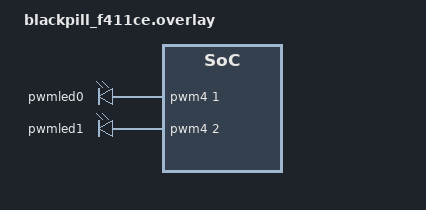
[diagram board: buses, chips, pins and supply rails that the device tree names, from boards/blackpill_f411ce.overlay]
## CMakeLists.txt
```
# SPDX-License-Identifier: BSL-1.0

cmake_minimum_required(VERSION 3.30)

find_package(Zephyr HINTS $ENV{ZEPHYR_BASE})

project(001-cmakepresets-json
        VERSION 1.0.0
        LANGUAGES C ASM
        DESCRIPTION "VS Code CMakePresets.json for Zephyr"
        HOMEPAGE_URL "https://github.com/juanjin-dev/learning-zephyr")

add_subdirectory(src)
```

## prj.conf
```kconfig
# SPDX-License-Identifier: BSL-1.0

CONFIG_PWM=y
CONFIG_LED=y
```

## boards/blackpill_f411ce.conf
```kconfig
# SPDX-License-Identifier: BSL-1.0
```

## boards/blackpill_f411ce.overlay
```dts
/**
 * SPDX-License-Identifier: BSL-1.0
 */

/ {
	pwmleds: pwmleds {
    	status = "okay";
		compatible = "pwm-leds";

		pwmled0: pwmled0 {
			pwms = <&pwm4 1 65535 PWM_POLARITY_NORMAL>;
		};

		pwmled1: pwmled1 {
			pwms = <&pwm4 2 65535 PWM_POLARITY_NORMAL>;
		};
	};
};
```

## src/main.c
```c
/**
 * SPDX-License-Identifier: BSL-1.0
 */

#include <zephyr/kernel.h>
#include <zephyr/drivers/led.h>
struct pwmled_data {
    const struct led_dt_spec pwmled;
    bool dir;
    uint8_t brightness;
};

int main(void) {
    int ret;
    struct k_timer timer;
    struct pwmled_data pwmleds[] = {
        {
            .pwmled = LED_DT_SPEC_GET(DT_NODELABEL(pwmled0)),
            .dir = false,
            .brightness = 0,
        },
        {
            .pwmled = LED_DT_SPEC_GET(DT_NODELABEL(pwmled1)),
            .dir = true,
            .brightness = 100,
        }
    };

    ARRAY_FOR_EACH_PTR(pwmleds, pwmled) {
        if (!led_is_ready_dt(&pwmled->pwmled)) {
            printk("Error: LED %s is not ready\n",
                    pwmled->pwmled.dev->name);
            goto out;
        }
    }

    k_timer_init(&timer, NULL, NULL);
    k_timer_start(&timer, K_NO_WAIT, K_MSEC(5));

    while (true) {
        int elapsed = k_timer_status_sync(&timer);
        if (elapsed > 1) {
            printk("Error: timer is %d ms late\n", elapsed);
            k_timer_stop(&timer);
            goto out;
        }

        ARRAY_FOR_EACH_PTR(pwmleds, pwmled) {
            ret = led_set_brightness_dt(&pwmled->pwmled, pwmled->brightness);
            if (ret) {
                printk("Error %d: failed to set pulse width\n", ret);
                k_timer_stop(&timer);
                goto out;
            }

            if (!pwmled->dir) {
                pwmled->brightness += 1;
            } else {
                pwmled->brightness -= 1;
            }

            if (pwmled->brightness == 0 || pwmled->brightness == 100) {
                pwmled->dir = !pwmled->dir;
            }
        }
    }

out:
    return 0;
}
```
